# MU3E_RUNCTL_MGMT_HOST register map
Vendor: Mu3e; Series: MU3E_FPGA_IP; File version: 26.3.3.0525
CMSIS-SVD description of the Run-Control Management Host CSR window. BaseAddress is 0 because this file describes the relative CSR aperture of the IP; system integration supplies the live slave base address.
Registers are 32-bit, read-only, reset 0x0 unless marked. A register's access mark holds for its fields unless they carry their own. Offsets are from the block's base; lines under a group give offsets from that group; [hi:lo] are bit positions; {n}, {i} and the like mark numbered series; 'fields as' and 'values as' point back to an identical list; <NAME> marks a mode.

## Memory map
0x00000000 RUNCTL_MGMT_HOST_CSR size 0x54 — Relative 21-word CSR aperture for the Run-Control Management Host. The window includes the Mu3e identity header, live status, counters, timestamp snapshots, and the LOCAL_CMD injection port.

## RUNCTL_MGMT_HOST_CSR — Relative 21-word CSR aperture for the Run-Control Management Host. The window includes the Mu3e identity header, live status, counters, timestamp snapshots, and the LOCAL_CMD injection port.
Base 0x00000000
0x00 UID reset 0x52434D48 — Software-visible IP identifier. Default ASCII "RCMH" (0x52434D48).
0x04 META rw — Read-multiplexed metadata word. Write page_sel[1:0] before reading back: 0=VERSION, 1=DATE, 2=GIT, 3=INSTANCE_ID.
  [1:0] page_sel — Selects the META read page.
0x08 CONTROL rw — CSR control register for reset masking, local-log flushing, and software control-path housekeeping.
0x0C STATUS — Live run-control receiver, host, upload, and reset state summary.
0x10 LAST_CMD — Last accepted command byte plus decoded payload shadow fields.
0x14 SCRATCH rw — General-purpose scratch register for software bring-up.
0x18 RUN_NUMBER — Shadow of the most recently received RUN_PREPARE run number. Synclink payload bytes are decoded in SWB reset-link order: least-significant byte first.
0x1C RESET_MASK — Latched reset assert/release mask shadow.
0x20 FPGA_ADDRESS — Latched per-FEB address from CMD_ADDRESS or LOCAL_CMD injection.
0x24 RECV_TS_L — Low 32 bits of the receive timestamp snapshot.
0x28 RECV_TS_H — High 16 bits of the receive timestamp snapshot.
0x2C EXEC_TS_L — Low 32 bits of the execute timestamp snapshot.
0x30 EXEC_TS_H — High 16 bits of the execute timestamp snapshot.
0x34 GTS_L — Low 32 bits of the free-running 48-bit global timestamp snapshot.
0x38 GTS_H — High 16 bits of the free-running 48-bit global timestamp snapshot.
0x3C RX_CMD_COUNT — Saturating count of accepted run-control commands.
0x40 RX_ERR_COUNT — Saturating count of receive-side protocol or decode errors.
0x44 LOG_STATUS — Status summary for the internal command log FIFO.
0x48 LOG_POP — Read port for the packed 128-bit log FIFO, exposed one 32-bit word at a time.
0x4C LOCAL_CMD rw — Software injection port for a local run-control command word.
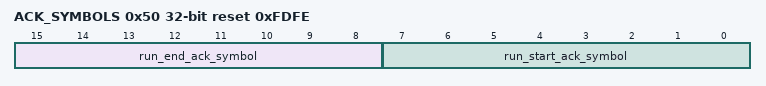
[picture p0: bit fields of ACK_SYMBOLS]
0x50 ACK_SYMBOLS reset 0xFDFE — Configured upload acknowledgement symbols for RUN_PREPARE and END_RUN. Reset/default value packs RUN_START_ACK_SYMBOL=0xFE in [7:0] and RUN_END_ACK_SYMBOL=0xFD in [15:8].
  [15:8] run_end_ack_symbol — END_RUN upload acknowledgement symbol. Default K29.7 = 0xFD.
  [7:0] run_start_ack_symbol — RUN_PREPARE upload acknowledgement symbol. Default K30.7 = 0xFE.
